# CY8C5888LTI_LP097 register map
File version: 0.1
CY8C58LP
Registers are 8-bit, read-write, no defined reset value unless marked. A register's access mark holds for its fields unless they carry their own. Offsets are from the block's base; lines under a group give offsets from that group; [hi:lo] are bit positions; {n}, {i} and the like mark numbered series; 'fields as' and 'values as' point back to an identical list; <NAME> marks a mode.

## Memory map
0x00000000 ctrl_snd
0x00000000 pwm_snd
0x00000000 usb_uart — USBFS
0x00000000 HORIZ
0x00000000 VSYNC
0x00000000 VERT
0x00000000 random
0x00000000 PIXEL
0x00000000 HSYNC

## ctrl_snd
Base 0x00000000
0x40006577 ctrl_snd_CONTROL_REG

## pwm_snd
Base 0x00000000
0x40006524 pwm_snd_COMPARE_Reg_ — UDB.D0 - Assigned Compare Value
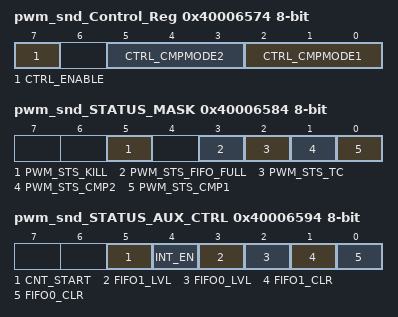
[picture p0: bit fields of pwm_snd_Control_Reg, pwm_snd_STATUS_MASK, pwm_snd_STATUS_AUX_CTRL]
0x40006574 pwm_snd_Control_Reg — UDB Control Register - Assigned Control Register Value
  [7] CTRL_ENABLE — Enable the PWM
  [5:3] CTRL_CMPMODE2 — Compare mode 2
  [2:0] CTRL_CMPMODE1 — Compare mode 1
0x40006584 pwm_snd_STATUS_MASK — UDB Status bits Interrupt Mask Enable Register
  [5] PWM_STS_KILL ro — Enables the Interrupt on Kill
  [3] PWM_STS_FIFO_FULL ro — FIFO Full Status Mask
  [2] PWM_STS_TC ro — Enables the Interrupt on Terminal Count
  [1] PWM_STS_CMP2 ro — Enables the Interrupt on Compare 2
  [0] PWM_STS_CMP1 ro — Enables the Interrupt on Compare 1
0x40006594 pwm_snd_STATUS_AUX_CTRL — UDB Auxilliary Control Register
  [5] CNT_START — FIFO0 clear
    0=E_CNT_START0 (Disable counter); 1=E_CNT_START1 (Enable counter)
  [4] INT_EN
    0=E_INT_EN0 (Interrupt disabled); 1=E_INT_EN1 (Interrupt enabled)
  [3] FIFO1_LVL — FIFO level
    0=E_FIFO_LVL_0 (FIFO LVL: input mode: FIFO not full; output mode: FIFO not empty); 1=E_FIFO_LVL_1 (FIFO LVL: input mode: FIFO at least 1/2 empty; output mode: FIFO at least 1/2 full)
  [2] FIFO0_LVL — FIFO level
    values as FIFO1_LVL
  [1] FIFO1_CLR — FIFO1 clear
    0=E_FIFO_CLR_0 (Normal FIFO operation); 1=E_FIFO_CLR_1 (Clear FIFO state)
  [0] FIFO0_CLR — FIFO0 clear
    values as FIFO1_CLR

## HORIZ
Base 0x00000000
0x40006422 HORIZ__COMPARE1 — UDB.D0 - Assigned Compare1 Value
0x40006432 HORIZ__COMPARE2 — UDB.D1 - Assigned Compare2 Value
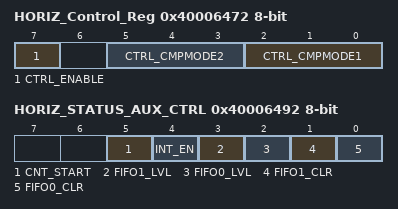
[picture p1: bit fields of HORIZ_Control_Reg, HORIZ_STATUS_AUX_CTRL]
0x40006472 HORIZ_Control_Reg — UDB Control Register - Assigned Control Register Value
  [7] CTRL_ENABLE — Enable the PWM
  [5:3] CTRL_CMPMODE2 — Compare mode 2
  [2:0] CTRL_CMPMODE1 — Compare mode 1
0x40006492 HORIZ_STATUS_AUX_CTRL — UDB Auxilliary Control Register
  [5] CNT_START — FIFO0 clear
    0=E_CNT_START0 (Disable counter); 1=E_CNT_START1 (Enable counter)
  [4] INT_EN
    0=E_INT_EN0 (Interrupt disabled); 1=E_INT_EN1 (Interrupt enabled)
  [3] FIFO1_LVL — FIFO level
    0=E_FIFO_LVL_0 (FIFO LVL: input mode: FIFO not full; output mode: FIFO not empty); 1=E_FIFO_LVL_1 (FIFO LVL: input mode: FIFO at least 1/2 empty; output mode: FIFO at least 1/2 full)
  [2] FIFO0_LVL — FIFO level
    values as FIFO1_LVL
  [1] FIFO1_CLR — FIFO1 clear
    0=E_FIFO_CLR_0 (Normal FIFO operation); 1=E_FIFO_CLR_1 (Clear FIFO state)
  [0] FIFO0_CLR — FIFO0 clear
    values as FIFO1_CLR

## VSYNC
Base 0x00000000
0x40006525 VSYNC_COMPARE_Reg_ — UDB.D0 - Assigned Compare Value
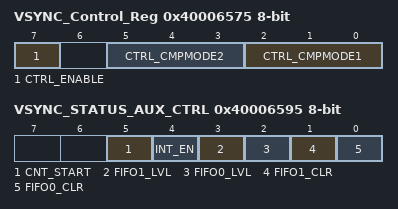
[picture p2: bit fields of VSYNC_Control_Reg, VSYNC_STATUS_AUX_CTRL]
0x40006575 VSYNC_Control_Reg — UDB Control Register - Assigned Control Register Value
  [7] CTRL_ENABLE — Enable the PWM
  [5:3] CTRL_CMPMODE2 — Compare mode 2
  [2:0] CTRL_CMPMODE1 — Compare mode 1
0x40006595 VSYNC_STATUS_AUX_CTRL — UDB Auxilliary Control Register
  [5] CNT_START — FIFO0 clear
    0=E_CNT_START0 (Disable counter); 1=E_CNT_START1 (Enable counter)
  [4] INT_EN
    0=E_INT_EN0 (Interrupt disabled); 1=E_INT_EN1 (Interrupt enabled)
  [3] FIFO1_LVL — FIFO level
    0=E_FIFO_LVL_0 (FIFO LVL: input mode: FIFO not full; output mode: FIFO not empty); 1=E_FIFO_LVL_1 (FIFO LVL: input mode: FIFO at least 1/2 empty; output mode: FIFO at least 1/2 full)
  [2] FIFO0_LVL — FIFO level
    values as FIFO1_LVL
  [1] FIFO1_CLR — FIFO1 clear
    0=E_FIFO_CLR_0 (Normal FIFO operation); 1=E_FIFO_CLR_1 (Clear FIFO state)
  [0] FIFO0_CLR — FIFO0 clear
    values as FIFO1_CLR
